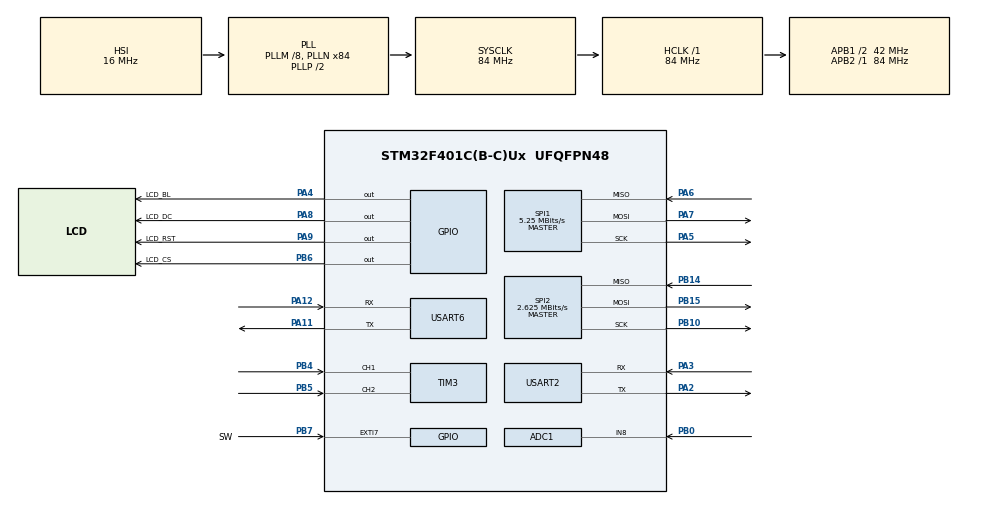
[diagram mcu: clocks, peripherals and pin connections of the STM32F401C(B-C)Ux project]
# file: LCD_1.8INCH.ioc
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ADC1.Channel-7\#ChannelRegularConversion=ADC_CHANNEL_8
ADC1.NbrOfConversionFlag=1
ADC1.Rank-7\#ChannelRegularConversion=1
ADC1.SamplingTime-7\#ChannelRegularConversion=ADC_SAMPLETIME_3CYCLES
ADC1.master=1
Mcu.Family=STM32F4
Mcu.Name=STM32F401C(B-C)Ux
Mcu.Package=UFQFPN48
NVIC.EXTI9_5_IRQn=true\:0\:0\:false\:false\:true\:true\:true\:true
NVIC.PriorityGroup=NVIC_PRIORITYGROUP_4
PA11.Mode=Asynchronous
PA11.Signal=USART6_TX
PA12.Mode=Asynchronous
PA12.Signal=USART6_RX
PA13.Mode=Serial_Wire
PA13.Signal=SYS_JTMS-SWDIO
PA14.Mode=Serial_Wire
PA14.Signal=SYS_JTCK-SWCLK
PA2.Mode=Asynchronous
PA2.Signal=USART2_TX
PA3.Mode=Asynchronous
PA3.Signal=USART2_RX
PA4.GPIO_Label=LCD_BL
PA4.Signal=GPIO_Output
PA5.GPIO_Speed=GPIO_SPEED_FREQ_VERY_HIGH
PA5.Mode=Full_Duplex_Master
PA5.Signal=SPI1_SCK
PA6.GPIO_Mode=GPIO_MODE_AF_PP
PA6.GPIO_Speed=GPIO_SPEED_FREQ_VERY_HIGH
PA6.Mode=Full_Duplex_Master
PA6.Signal=SPI1_MISO
PA7.GPIO_Speed=GPIO_SPEED_FREQ_VERY_HIGH
PA7.Mode=Full_Duplex_Master
PA7.Signal=SPI1_MOSI
PA8.GPIO_Label=LCD_DC
PA8.Signal=GPIO_Output
PA9.GPIO_Label=LCD_RST
PA9.Signal=GPIO_Output
PB0.Signal=ADCx_IN8
PB10.Mode=Full_Duplex_Master
PB10.Signal=SPI2_SCK
PB14.Mode=Full_Duplex_Master
PB14.Signal=SPI2_MISO
PB15.Mode=Full_Duplex_Master
PB15.Signal=SPI2_MOSI
PB4.Signal=S_TIM3_CH1
PB5.Signal=S_TIM3_CH2
PB6.GPIO_Label=LCD_CS
PB6.Signal=GPIO_Output
PB7.GPIO_Label=SW
PB7.GPIO_ModeDefaultEXTI=GPIO_MODE_IT_RISING_FALLING
PB7.Signal=GPXTI7
PH0\ -\ OSC_IN.Mode=HSE-External-Clock-Source
PH0\ -\ OSC_IN.Signal=RCC_OSC_IN
PH1\ -\ OSC_OUT.Mode=HSE-External-Clock-Source
PH1\ -\ OSC_OUT.Signal=RCC_OSC_OUT
ProjectManager.HeapSize=0x200
ProjectManager.StackSize=0x400
ProjectManager.TargetToolchain=STM32CubeIDE
RCC.48MHZClocksFreq_Value=42000000
RCC.AHBFreq_Value=84000000
RCC.APB1CLKDivider=RCC_HCLK_DIV2
RCC.APB1Freq_Value=42000000
RCC.APB1TimFreq_Value=84000000
RCC.APB2Freq_Value=84000000
RCC.APB2TimFreq_Value=84000000
RCC.CortexFreq_Value=84000000
RCC.HCLKFreq_Value=84000000
RCC.HSE_VALUE=25000000
RCC.HSI_VALUE=16000000
RCC.LSE_VALUE=32768
RCC.PLLM=8
RCC.PLLN=84
RCC.SYSCLKFreq_VALUE=84000000
RCC.SYSCLKSource=RCC_SYSCLKSOURCE_PLLCLK
RCC.VCOOutputFreq_Value=168000000
SH.ADCx_IN8.0=ADC1_IN8,IN8
SH.S_TIM3_CH1.0=TIM3_CH1,Encoder_Interface
SH.S_TIM3_CH2.0=TIM3_CH2,Encoder_Interface
SPI1.BaudRatePrescaler=SPI_BAUDRATEPRESCALER_16
SPI1.CalculateBaudRate=5.25 MBits/s
SPI1.Direction=SPI_DIRECTION_2LINES
SPI1.Mode=SPI_MODE_MASTER
SPI1.VirtualType=VM_MASTER
SPI2.BaudRatePrescaler=SPI_BAUDRATEPRESCALER_16
SPI2.CalculateBaudRate=2.625 MBits/s
SPI2.Direction=SPI_DIRECTION_2LINES
SPI2.Mode=SPI_MODE_MASTER
SPI2.VirtualType=VM_MASTER
USART2.VirtualMode=VM_ASYNC
USART6.VirtualMode=VM_ASYNC
board=custom

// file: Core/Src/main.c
/* USER CODE BEGIN Header */
/**
  ******************************************************************************
  * @file           : main.c
  * @brief          : Main program body
  ******************************************************************************
  * @attention
  *
  * Copyright (c) 2022 STMicroelectronics.
  * All rights reserved.
  *
  * This software is licensed under terms that can be found in the LICENSE file
  * in the root directory of this software component.
  * If no LICENSE file comes with this software, it is provided AS-IS.
  *
  ******************************************************************************
  */
/* USER CODE END Header */
#include "main.h"
#include "adc.h"
#include "spi.h"
#include "tim.h"
#include "usart.h"
#include "gpio.h"

/* USER CODE BEGIN Includes */
#include "LCD.h"
#include <stdio.h>
#include "DEV_Config.h"
/* USER CODE END Includes */

/* USER CODE BEGIN PV */
uint16_t bouncetime=0;

/* USER CODE END PV */

void SystemClock_Config(void);

int main(void)
{

  /* MCU Configuration--------------------------------------------------------*/

  /* Reset of all peripherals, Initializes the Flash interface and the Systick. */
  HAL_Init();

  /* Configure the system clock */
  SystemClock_Config();

  /* Initialize all configured peripherals */
  MX_GPIO_Init();
  MX_SPI1_Init();
  MX_USART2_UART_Init();
  MX_ADC1_Init();
  MX_SPI2_Init();
  MX_TIM3_Init();
  MX_USART6_UART_Init();
  /* USER CODE BEGIN 2 */
 // printf("**********Init LCD**********\r\n");
  	LCD_SCAN_DIR Lcd_ScanDir = SCAN_DIR_DFT;//SCAN_DIR_DFT = D2U_L2R
  	LCD_Init( Lcd_ScanDir );
  	//printf("LCD Show \r\n");
  		LCD_Show();
  		Driver_Delay_ms(1000);

  		LCD_Clear(RED);
  /* USER CODE END 2 */

  /* Infinite loop */
  while (1)
  {

  }
}

void SystemClock_Config(void)
{
  RCC_OscInitTypeDef RCC_OscInitStruct = {0};
  RCC_ClkInitTypeDef RCC_ClkInitStruct = {0};

  /** Configure the main internal regulator output voltage
  */
  __HAL_RCC_PWR_CLK_ENABLE();
  __HAL_PWR_VOLTAGESCALING_CONFIG(PWR_REGULATOR_VOLTAGE_SCALE2);

  /** Initializes the RCC Oscillators according to the specified parameters
  * in the RCC_OscInitTypeDef structure.
  */
  RCC_OscInitStruct.OscillatorType = RCC_OSCILLATORTYPE_HSI;
  RCC_OscInitStruct.HSIState = RCC_HSI_ON;
  RCC_OscInitStruct.HSICalibrationValue = RCC_HSICALIBRATION_DEFAULT;
  RCC_OscInitStruct.PLL.PLLState = RCC_PLL_ON;
  RCC_OscInitStruct.PLL.PLLSource = RCC_PLLSOURCE_HSI;
  RCC_OscInitStruct.PLL.PLLM = 8;
  RCC_OscInitStruct.PLL.PLLN = 84;
  RCC_OscInitStruct.PLL.PLLP = RCC_PLLP_DIV2;
  RCC_OscInitStruct.PLL.PLLQ = 4;
  if (HAL_RCC_OscConfig(&RCC_OscInitStruct) != HAL_OK)
  {
    Error_Handler();
  }

  /** Initializes the CPU, AHB and APB buses clocks
  */
  RCC_ClkInitStruct.ClockType = RCC_CLOCKTYPE_HCLK|RCC_CLOCKTYPE_SYSCLK
                              |RCC_CLOCKTYPE_PCLK1|RCC_CLOCKTYPE_PCLK2;
  RCC_ClkInitStruct.SYSCLKSource = RCC_SYSCLKSOURCE_PLLCLK;
  RCC_ClkInitStruct.AHBCLKDivider = RCC_SYSCLK_DIV1;
  RCC_ClkInitStruct.APB1CLKDivider = RCC_HCLK_DIV2;
  RCC_ClkInitStruct.APB2CLKDivider = RCC_HCLK_DIV1;

  if (HAL_RCC_ClockConfig(&RCC_ClkInitStruct, FLASH_LATENCY_2) != HAL_OK)
  {
    Error_Handler();
  }
}

/* USER CODE BEGIN 4 */
void HAL_GPIO_EXTI_Callback(uint16_t GPIO_Pin)
	{

		if(GPIO_Pin == SW_Pin && (bouncetime-HAL_GetTick())>20)
		{	if(HAL_GPIO_ReadPin(SW_GPIO_Port, SW_Pin)==1)
			{
				HAL_Delay(10);//JAKIES GOWNO DO OBSLUZENIA
			}

			bouncetime=HAL_GetTick();
		}

	}
/* USER CODE END 4 */

void Error_Handler(void)
{
  __disable_irq();
  while (1)
  {
  }
}
